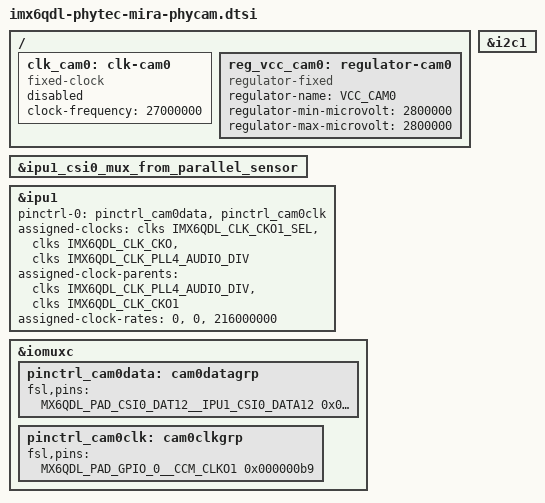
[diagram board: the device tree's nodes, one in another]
// SPDX-License-Identifier: (GPL-2.0+ OR MIT)
/*
 * Copyright (C) 2020 PHYTEC Messtechnik GmbH
 * Author: Stefan Riedmueller <s.riedmueller@phytec.de>
 */

/ {
	clk_cam0: clk-cam0 {
		#clock-cells = <0>;

		compatible = "fixed-clock";
		clock-frequency = <27000000>;
		status = "disabled";
	};

	reg_vcc_cam0: regulator-cam0 {
		compatible = "regulator-fixed";
		regulator-name = "VCC_CAM0";
		regulator-min-microvolt = <2800000>;
		regulator-max-microvolt = <2800000>;
	};
};

cam0_i2c: &i2c1 {};
cam0_ep: &ipu1_csi0_mux_from_parallel_sensor {};

&ipu1 {
	pinctrl-names = "default";
	pinctrl-0 = <
		&pinctrl_cam0data
		&pinctrl_cam0clk
	>;

	assigned-clocks =
		<&clks IMX6QDL_CLK_CKO1_SEL>,
		<&clks IMX6QDL_CLK_CKO>,
		<&clks IMX6QDL_CLK_PLL4_AUDIO_DIV>;

	assigned-clock-parents =
		<&clks IMX6QDL_CLK_PLL4_AUDIO_DIV>,
		<&clks IMX6QDL_CLK_CKO1>;

	assigned-clock-rates = <0>, <0>, <216000000>;
};

&iomuxc {
	pinctrl_cam0data: cam0datagrp {
		fsl,pins = <
			MX6QDL_PAD_CSI0_DAT12__IPU1_CSI0_DATA12 0x0001b0b0
			MX6QDL_PAD_CSI0_DAT13__IPU1_CSI0_DATA13 0x0001b0b0
			MX6QDL_PAD_CSI0_DAT14__IPU1_CSI0_DATA14 0x0001b0b0
			MX6QDL_PAD_CSI0_DAT15__IPU1_CSI0_DATA15 0x0001b0b0
			MX6QDL_PAD_CSI0_DAT16__IPU1_CSI0_DATA16 0x0001b0b0
			MX6QDL_PAD_CSI0_DAT17__IPU1_CSI0_DATA17 0x0001b0b0
			MX6QDL_PAD_CSI0_DAT18__IPU1_CSI0_DATA18 0x0001b0b0
			MX6QDL_PAD_CSI0_DAT19__IPU1_CSI0_DATA19 0x0001b0b0
			MX6QDL_PAD_CSI0_MCLK__IPU1_CSI0_HSYNC   0x0001b0b0
			MX6QDL_PAD_CSI0_PIXCLK__IPU1_CSI0_PIXCLK 0x4001b0b0
			MX6QDL_PAD_CSI0_VSYNC__IPU1_CSI0_VSYNC  0x0001b0b0
		>;
	};

	pinctrl_cam0clk: cam0clkgrp {
		fsl,pins = <MX6QDL_PAD_GPIO_0__CCM_CLKO1	0x000000b9>;
	};
};
